VERSION ""

NS_ :

BS_:

BU_:

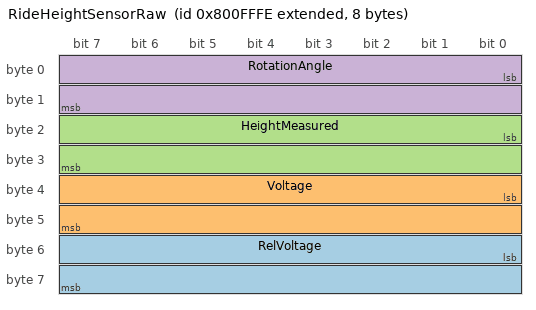
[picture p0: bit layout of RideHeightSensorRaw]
BO_ 2281766910 RideHeightSensorRaw: 8 Vector__XXX
 SG_ RelVoltage : 48|16@1+ (0.002,0) [0|100] "" Vector__XXX
 SG_ Voltage : 32|16@1+ (0.0001,0) [0|6.5535] "V" Vector__XXX
 SG_ HeightMeasured : 16|16@1- (0.01,0) [-327.68|327.67] "mm" Vector__XXX
 SG_ RotationAngle : 0|16@1+ (0.01,0) [0|360] "deg" Vector__XXX

BO_ 2214658046 RideHeightSensorInfo: 8 Vector__XXX
 SG_ RideHeightFigureOfMerit : 8|2@1+ (1,0) [0|3] "" Vector__XXX
 SG_ RideHeight : 16|16@1- (0.01,0) [-327.68|327.67] "mm" Vector__XXX

CM_ BO_ 2281766910 "Ride Height Sensor Raw Information
This message shall provide raw measurements from corresponding sensor";
CM_ SG_ 2281766910 HeightMeasured "HeightMeasured = L*sin(RotationAngle), where L - sensor lever, default 50 mm accordance to Swoboda Ride Height Sensor specification";
CM_ SG_ 2281766910 RotationAngle "Raw Rotation Angle value which is obtained using the voltage-degree characteristic from Swoboda Ride Height Sensorspecification";
CM_ BO_ 2214658046 "Ride Height Sensor Information
The Ride Height Sensor Information message shall provide a measurement of ride height which is received from corresponding sensor on one of vehicle axles ";
CM_ SG_ 2214658046 RideHeightFigureOfMerit "Figure of merit for ride height measurement.

00 - Ride height fully functional.  Data is within sensor specification. 
01 - Ride height degraded.  Data is suspect due to environmental conditions.
10 - Error
11 - Not available";
CM_ SG_ 2214658046 RideHeight "Axle ride height including distance unsprung mass";
BA_DEF_ BO_  "Producer" STRING ;
BA_DEF_ SG_  "SigType" ENUM  "Default","Range","RangeSigned","ASCII","Discrete","Control","ReferencePGN","DTC","StringDelimiter","StringLength","StringLengthControl","MessageCounter","MessageChecksum";
BA_DEF_ SG_  "GenSigEVName" STRING ;
BA_DEF_ SG_  "GenSigILSupport" ENUM  "No","Yes";
BA_DEF_ SG_  "GenSigSendType" ENUM  "Cyclic","OnWrite","OnWriteWithRepetition","OnChange","OnChangeWithRepetition","IfActive","IfActiveWithRepetition","NoSigSendType";
BA_DEF_ SG_  "GenSigStartValue" INT 0 2147483647;
BA_DEF_ BO_  "GenMsgILSupport" ENUM  "No","Yes";
BA_DEF_ BU_  "NmStationAddress" INT 0 255;
BA_DEF_ BO_  "GenMsgSendType" ENUM  "cyclic","NotUsed","IfActive","NotUsed","NotUsed","NotUsed","NotUsed","NotUsed","noMsgSendType";
BA_DEF_ BO_  "GenMsgRequestable" INT 0 1;
BA_DEF_ BO_  "GenMsgCycleTime" INT 0 3600000;
BA_DEF_  "DBName" STRING ;
BA_DEF_  "BusType" STRING ;
BA_DEF_  "ProtocolType" STRING ;
BA_DEF_ BO_  "VFrameFormat" ENUM  "StandardCAN","ExtendedCAN","reserved","J1939PG";
BA_DEF_DEF_ "Producer" "SCS" ;
BA_DEF_DEF_  "SigType" "Default";
BA_DEF_DEF_  "GenSigEVName" "Env@Nodename_@Signame";
BA_DEF_DEF_  "GenSigILSupport" "Yes";
BA_DEF_DEF_  "GenSigSendType" "NoSigSendType";
BA_DEF_DEF_  "GenSigStartValue" 0;
BA_DEF_DEF_  "GenMsgILSupport" "Yes";
BA_DEF_DEF_  "NmStationAddress" 254;
BA_DEF_DEF_  "GenMsgSendType" "noMsgSendType";
BA_DEF_DEF_  "GenMsgRequestable" 1;
BA_DEF_DEF_  "GenMsgCycleTime" 0;
BA_DEF_DEF_  "DBName" "";
BA_DEF_DEF_  "BusType" "CAN";
BA_DEF_DEF_  "ProtocolType" "J1939";
BA_DEF_DEF_  "VFrameFormat" "J1939PG";
BA_ "DBName" "Clearance";
BA_ "GenMsgCycleTime" BO_ 2281766910 100;
BA_ "GenMsgSendType" BO_ 2281766910 0;
BA_ "GenMsgCycleTime" BO_ 2214658046 100;
BA_ "GenMsgSendType" BO_ 2214658046 0;
VAL_ 2214658046 RideHeightFigureOfMerit 3 "Ride Height Not Available" 2 "Ride Height Error" 1 "Ride Height degraded" 0 "Ride Height fully functional" ;
